# M480_v1 register map
File version: 1.0
Registers are 32-bit, read-write, reset 0x0 unless marked. A register's access mark holds for its fields unless they carry their own. Offsets are from the block's base; [hi:lo] are bit positions; {n}, {i} and the like mark numbered series.

## RTC — RTC Register Map
Base 0x40041000
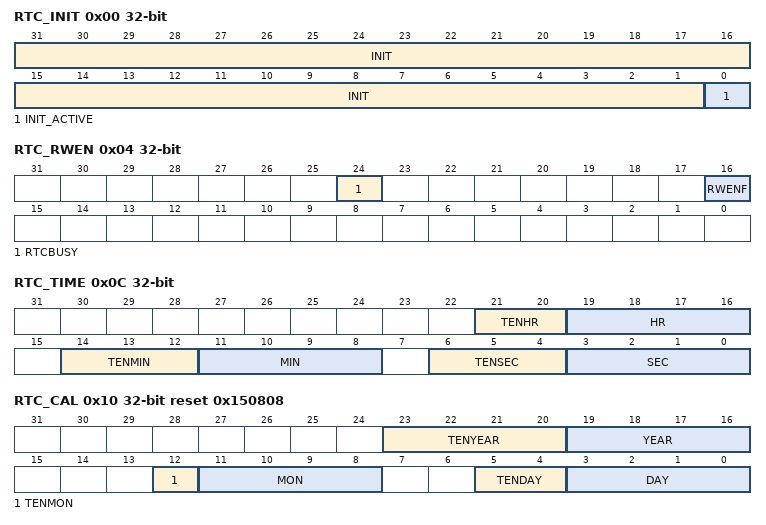
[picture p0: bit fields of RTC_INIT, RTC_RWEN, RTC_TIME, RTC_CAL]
0x00 RTC_INIT — RTC Initiation Register
  [31:1] INIT wo — RTC Initiation (Write Only). When RTC block is powered on, RTC is at reset state. User has to write a number (0x a5eb1357) to INIT to make RTC leave reset state. Once the INIT is written as 0xa5eb1357, the RTC will be in un-reset state permanently. The INIT is a write-only field and read value will be always 0.
  [0] INIT_ACTIVE ro — RTC Active Status (Read Only)
    0=RTC is at reset state; 1=RTC is at normal active state
0x04 RTC_RWEN — RTC Access Enable Register
  [24] RTCBUSY — RTC Write Busy Flag. This bit indicates RTC registers are writable or not. Note: RTCBUSY flag will be set when execute write RTC register command exceed 6 times within 1120 PCLK cycles.
    0=RTC registers are writable; 1=RTC registers can't be written. RTC is under Busy Status
  [16] RWENF ro — RTC Register Access Enable Flag (Read Only). Note: RWENF will be masked to 0 during RTCBUSY is 1, and first turn on RTCCKEN (CLK_APBCLK[1]) also.
    0=RTC register read/write Disabled; 1=RTC register read/write Enabled
0x08 RTC_FREQADJ reset 0x200000 — RTC Frequency Compensation Register
  [21:0] FREQADJ — Frequency Compensation Register. User must to get actual LXT frequency for RTC application. Note: This formula is suitable only when RTC clock source is from LXT, RTCSEL (CLK_CLKSEL3[8]) is 0.
0x0C RTC_TIME — RTC Time Loading Register
  [21:20] TENHR — 10-Hour Time Digit (0~2)When RTC runs as 12-hour time scale mode, RTC_TIME[21] (the high bit of TENHR[1:0]) means AM/PM indication (If RTC_TIME[21] is 1, it indicates PM time message.)
  [19:16] HR — 1-Hour Time Digit (0~9)
  [14:12] TENMIN — 10-Min Time Digit (0~5)
  [11:8] MIN — 1-Min Time Digit (0~9)
  [6:4] TENSEC — 10-Sec Time Digit (0~5)
  [3:0] SEC — 1-Sec Time Digit (0~9)
0x10 RTC_CAL reset 0x150808 — RTC Calendar Loading Register
  [23:20] TENYEAR — 10-Year Calendar Digit (0~9)
  [19:16] YEAR — 1-Year Calendar Digit (0~9)
  [12] TENMON — 10-Month Calendar Digit (0~1)
  [11:8] MON — 1-Month Calendar Digit (0~9)
  [5:4] TENDAY — 10-Day Calendar Digit (0~3)
  [3:0] DAY — 1-Day Calendar Digit (0~9)
0x14 RTC_CLKFMT reset 0x1 — RTC Time Scale Selection Register
  [0] _24HEN — 24-hour / 12-hour Time Scale Selection. Indicates that RTC_TIME and RTC_TALM are in 24-hour time scale or 12-hour time scale
    0=12-hour time scale with AM and PM indication selected; 1=24-hour time scale selected
0x18 RTC_WEEKDAY reset 0x6 — RTC Day of the Week Register
  [2:0] WEEKDAY — Day of the Week Register
    0=Sunday; 1=Monday; 2=Tuesday; 3=Wednesday; 4=Thursday; 5=Friday; 6=Saturday
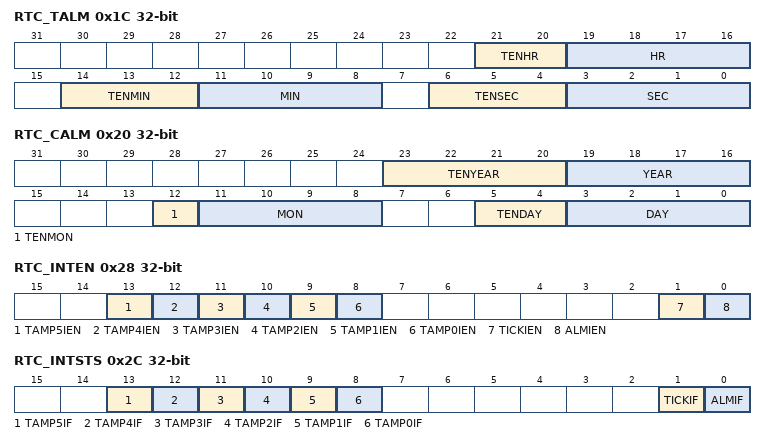
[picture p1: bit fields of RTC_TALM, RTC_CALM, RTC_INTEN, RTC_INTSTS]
0x1C RTC_TALM — RTC Time Alarm Register
  [21:20] TENHR — 10-Hour Time Digit of Alarm Setting (0~2)When RTC runs as 12-hour time scale mode, RTC_TIME[21] (the high bit of TENHR[1:0]) means AM/PM indication (If RTC_TIME[21] is 1, it indicates PM time message.)
  [19:16] HR — 1-Hour Time Digit of Alarm Setting (0~9)
  [14:12] TENMIN — 10-Min Time Digit of Alarm Setting (0~5)
  [11:8] MIN — 1-Min Time Digit of Alarm Setting (0~9)
  [6:4] TENSEC — 10-Sec Time Digit of Alarm Setting (0~5)
  [3:0] SEC — 1-Sec Time Digit of Alarm Setting (0~9)
0x20 RTC_CALM — RTC Calendar Alarm Register
  [23:20] TENYEAR — 10-Year Calendar Digit of Alarm Setting (0~9)
  [19:16] YEAR — 1-Year Calendar Digit of Alarm Setting (0~9)
  [12] TENMON — 10-Month Calendar Digit of Alarm Setting (0~1)
  [11:8] MON — 1-Month Calendar Digit of Alarm Setting (0~9)
  [5:4] TENDAY — 10-Day Calendar Digit of Alarm Setting (0~3)
  [3:0] DAY — 1-Day Calendar Digit of Alarm Setting (0~9)
0x24 RTC_LEAPYEAR ro — RTC Leap Year Indicator Register
  [0] LEAPYEAR — Leap Year Indication (Read Only)
    0=This year is not a leap year; 1=This year is leap year
0x28 RTC_INTEN — RTC Interrupt Enable Register
  [13] TAMP5IEN — Tamper 5 or Pair 2 Interrupt Enable Bit. Set TAMP5IEN to 1 can also enable chip wake-up function when tamper 5 interrupt event is generated.
    0=Tamper 5 or Pair 2 interrupt Disabled; 1=Tamper 5 or Pair 2 interrupt Enabled
  [12] TAMP4IEN — Tamper 4 Interrupt Enable Bit. Set TAMP4IEN to 1 can also enable chip wake-up function when tamper 4 interrupt event is generated.
    0=Tamper 4 interrupt Disabled; 1=Tamper 4 interrupt Enabled
  [11] TAMP3IEN — Tamper 3 or Pair 1 Interrupt Enable Bit. Set TAMP3IEN to 1 can also enable chip wake-up function when tamper 3 interrupt event is generated.
    0=Tamper 3 or Pair 1 interrupt Disabled; 1=Tamper 3 or Pair 1 interrupt Enabled
  [10] TAMP2IEN — Tamper 2 Interrupt Enable Bit. Set TAMP2IEN to 1 can also enable chip wake-up function when tamper 2 interrupt event is generated.
    0=Tamper 2 interrupt Disabled; 1=Tamper 2 interrupt Enabled
  [9] TAMP1IEN — Tamper 1 or Pair 0 Interrupt Enable Bit. Set TAMP1IEN to 1 can also enable chip wake-up function when tamper 1 interrupt event is generated.
    0=Tamper 1 or Pair 0 interrupt Disabled; 1=Tamper 1 or Pair 0 interrupt Enabled
  [8] TAMP0IEN — Tamper 0 Interrupt Enable Bit. Set TAMP0IEN to 1 can also enable chip wake-up function when tamper 0 interrupt event is generated.
    0=Tamper 0 interrupt Disabled; 1=Tamper 0 interrupt Enabled
  [1] TICKIEN — Time Tick Interrupt Enable Bit. Set TICKIEN to 1 can also enable chip wake-up function when RTC tick interrupt event is generated.
    0=RTC Time Tick interrupt Disabled; 1=RTC Time Tick interrupt Enabled
  [0] ALMIEN — Alarm Interrupt Enable Bit. Set ALMIEN to 1 can also enable chip wake-up function when RTC alarm interrupt event is generated.
    0=RTC Alarm interrupt Disabled; 1=RTC Alarm interrupt Enabled
0x2C RTC_INTSTS — RTC Interrupt Status Register
  [13] TAMP5IF — Tamper 5 or Pair 2 Interrupt Flag. This bit is set when TAMP5_PIN detected level non-equal TAMP5LV (RTC_TAMPCTL[29]) or TAMP4_PIN and TAMP5_PIN disconnected during DYNPR2EN (RTC_TAMPCTL[31]) is activated or TAMP0_PIN and TAMP5_PIN disconnected during DYNPR2EN (RTC_TAMPCTL[31]) and DYN2ISS (RTC_TAMPCTL[1]) are activated. Note1: Write 1 to clear this bit. Note2: Clear all TAPMxIF will clear RTC_TAMPTIME and RTC_TAMPCAL automatically.
    0=No Tamper 5 or Pair 2 interrupt flag is generated; 1=Tamper 5 or Pair 2 interrupt flag is generated
  [12] TAMP4IF — Tamper 4 Interrupt Flag. This bit is set when TAMP4_PIN detected level non-equal TAMP4LV (RTC_TAMPCTL[25]). Note1: Write 1 to clear this bit. Note2: Clear all TAPMxIF will clear RTC_TAMPTIME and RTC_TAMPCAL automatically.
    0=No Tamper 4 interrupt flag is generated; 1=Tamper 4 interrupt flag is generated
  [11] TAMP3IF — Tamper 3 or Pair 1 Interrupt Flag. This bit is set when TAMP3_PIN detected level non-equal TAMP3LV (RTC_TAMPCTL[21]) or TAMP2_PIN and TAMP3_PIN disconnected during DYNPR1EN (RTC_TAMPCTL[23]) is activated or TAMP0_PIN and TAMP3_PIN disconnected during DYNPR1EN (RTC_TAMPCTL[23]) and DYN1ISS (RTC_TAMPCTL[0]) are activated. Note1: Write 1 to clear this bit. Note2: Clear all TAPMxIF will clear RTC_TAMPTIME and RTC_TAMPCAL automatically.
    0=No Tamper 3 or Pair 1 interrupt flag is generated; 1=Tamper 3 or Pair 1 interrupt flag is generated
  [10] TAMP2IF — Tamper 2 Interrupt Flag. This bit is set when TAMP2_PIN detected level non-equal TAMP2LV (RTC_TAMPCTL[17]). Note1: Write 1 to clear this bit. Note2: Clear all TAPMxIF will clear RTC_TAMPTIME and RTC_TAMPCAL automatically.
    0=No Tamper 2 interrupt flag is generated; 1=Tamper 2 interrupt flag is generated
  [9] TAMP1IF — Tamper 1 or Pair 0 Interrupt Flag. This bit is set when TAMP1_PIN detected level non-equal TAMP1LV (RTC_TAMPCTL[13]) or TAMP0_PIN and TAMP1_PIN disconnected during DYNPR0EN (RTC_TAMPCTL[15]) is activated. Note1: Write 1 to clear this bit. Note2: Clear all TAPMxIF will clear RTC_TAMPTIME and RTC_TAMPCAL automatically.
    0=No Tamper 1 or Pair 0 interrupt flag is generated; 1=Tamper 1 or Pair 0 interrupt flag is generated
  [8] TAMP0IF — Tamper 0 Interrupt Flag. This bit is set when TAMP0_PIN detected level non-equal TAMP0LV (RTC_TAMPCTL[9]). Note1: Write 1 to clear this bit. Note2: Clear all TAPMxIF will clear RTC_TAMPTIME and RTC_TAMPCAL automatically.
    0=No Tamper 0 interrupt flag is generated; 1=Tamper 0 interrupt flag is generated
  [1] TICKIF — RTC Time Tick Interrupt Flag. Note: Write 1 to clear this bit.
    0=Tick condition did not occur; 1=Tick condition occurred
  [0] ALMIF — RTC Alarm Interrupt Flag. Note: Write 1 to clear this bit.
    0=Alarm condition is not matched; 1=Alarm condition is matched
0x30 RTC_TICK — RTC Time Tick Register
  [2:0] TICK — Time Tick Register. These bits are used to select RTC time tick period for Periodic Time Tick Interrupt request. Note: This register can be read back after the RTC register access enable bit RWENF (RTC_RWEN[16]) is active.
    0=Time tick is 1 second; 1=Time tick is 1/2 second; 2=Time tick is 1/4 second; 3=Time tick is 1/8 second; 4=Time tick is 1/16 second; 5=Time tick is 1/32 second; 6=Time tick is 1/64 second; 7=Time tick is 1/128 second
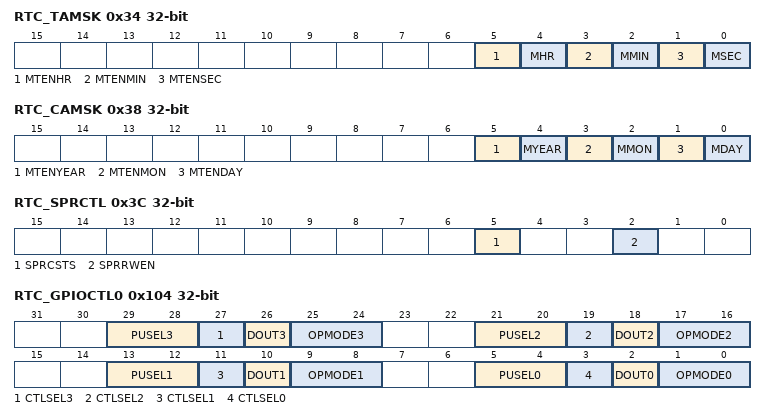
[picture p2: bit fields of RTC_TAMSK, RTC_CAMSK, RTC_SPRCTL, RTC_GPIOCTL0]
0x34 RTC_TAMSK — RTC Time Alarm Mask Register
  [5] MTENHR — Mask 10-Hour Time Digit of Alarm Setting (0~2)
  [4] MHR — Mask 1-Hour Time Digit of Alarm Setting (0~9)
  [3] MTENMIN — Mask 10-Min Time Digit of Alarm Setting (0~5)
  [2] MMIN — Mask 1-Min Time Digit of Alarm Setting (0~9)
  [1] MTENSEC — Mask 10-Sec Time Digit of Alarm Setting (0~5)
  [0] MSEC — Mask 1-Sec Time Digit of Alarm Setting (0~9)
0x38 RTC_CAMSK — RTC Calendar Alarm Mask Register
  [5] MTENYEAR — Mask 10-Year Calendar Digit of Alarm Setting (0~9)
  [4] MYEAR — Mask 1-Year Calendar Digit of Alarm Setting (0~9)
  [3] MTENMON — Mask 10-Month Calendar Digit of Alarm Setting (0~1)
  [2] MMON — Mask 1-Month Calendar Digit of Alarm Setting (0~9)
  [1] MTENDAY — Mask 10-Day Calendar Digit of Alarm Setting (0~3)
  [0] MDAY — Mask 1-Day Calendar Digit of Alarm Setting (0~9)
0x3C RTC_SPRCTL — RTC Spare Functional Control Register
  [5] SPRCSTS — SPR Clear Flag. This bit indicates if the RTC_SPR0 ~RTC_SPR19 content is cleared when specify tamper event is detected. Note1: Write 1 to clear this bit. Note2: This bit keeps 1 when RTC_INTSTS[13:8] is not equal to 0.
    0=Spare register content is not cleared; 1=Spare register content is cleared
  [2] SPRRWEN — Spare Register Enable Bit. Note: When spare register is disabled, RTC_SPR0 ~ RTC_SPR19 cannot be accessed.
    0=Spare register Disabled; 1=Spare register Enabled
{0x40+4i} RTC_SPR{i} (i=0..19) — RTC Spare Register {i}
  [31:0] SPARE — Spare Register. This field is used to store back-up information defined by user. This field will be cleared by hardware automatically once a tamper pin event is detected. Before storing back-up information in to RTC_SPRx register, user should check REWNF (RTC_RWEN[16]) is enabled.
0x100 RTC_LXTCTL reset 0xE — RTC 32.768 KHz Oscillator Control Register
  [2:1] GAIN — Oscillator Gain Option. User can select oscillator gain according to crystal external loading and operating temperature range. The larger gain value corresponding to stronger driving capability and higher power consumption.
    {v}=L{v} mode (v=0..3)
0x104 RTC_GPIOCTL0 — RTC GPIO Control 0 Register
  [29:28] PUSEL3 — IO Pull-up and Pull-down Enable Bits. Determine PF.7 I/O pull-up or pull-down. Note: Basically, the pull-up control and pull-down control has following behavior limitation. The independent pull-up / pull-down control register only valid when OPMODE2 set as input tri-state and open-drain mode.
    0=PF.7 pull-up and pull-down disable; 1=PF.7 pull-up enable; 2=PF.7 pull-down enable
  [27] CTLSEL3 — IO Pin State Backup Selection. When TAMP1EN is disabled, PF.7 pin (TAMPER1 pin) can be used as GPIO function. User can program CTLSEL3 to decide PF.7 I/O function is controlled by system power domain GPIO module or VBAT power domain RTC_GPIOCTL0 control register. PF.7 pin function and I/O status are controlled by OPMODE3[1:0] and DOUT3 after CTLSEL3 is set to 1. Note: CTLSEL3 will automatically be set by hardware to 1 when system power is off and INIT[0](RTC_INIT[0]) is 1.
    0=PF.7 pin I/O function is controlled by GPIO module; 1=PF.7 pin I/O function is controlled by VBAT power domain
  [26] DOUT3 — IO Output Data
    0=PF.7 output low; 1=PF.7 output high
  [25:24] OPMODE3 — IO Operation Mode
    0=PF.7 is input only mode; 1=PF.7 is output push pull mode; 2=PF.7 is open drain mode; 3=PF.7 is quasi-bidirectional mode
  [21:20] PUSEL2 — IO Pull-up and Pull-down Enable Bits. Determine PF.6 I/O pull-up or pull-down. Note1: Basically, the pull-up control and pull-down control has following behavior limitation. The independent pull-up / pull-down control register only valid when OPMODE2 set as input tri-state and open-drain mode.
    0=PF.6 pull-up and pull-down disable; 1=PF.6 pull-up enable; 2=PF.6 pull-down enable
  [19] CTLSEL2 — IO Pin State Backup Selection. When TAMP0EN is disabled, PF.6 pin (TAMPER0 pin) can be used as GPIO function. User can program CTLSEL2 to decide PF.6 I/O function is controlled by system power domain GPIO module or VBAT power domain RTC_GPIOCTL0 control register. PF.6 pin function and I/O status are controlled by OPMODE2[1:0] and DOUT2 after CTLSEL2 is set to 1. Note: CTLSEL2 will automatically be set by hardware to 1 when system power is off and INIT[0] (RTC_INIT[0]) is 1.
    0=PF.6 pin I/O function is controlled by GPIO module; 1=PF.6 pin I/O function is controlled by VBAT power domain
  [18] DOUT2 — IO Output Data
    0=PF.6 output low; 1=PF.6 output high
  [17:16] OPMODE2 — IO Operation Mode
    0=PF.6 is input only mode; 1=PF.6 is output push pull mode; 2=PF.6 is open drain mode; 3=PF.6 is quasi-bidirectional mode
  [13:12] PUSEL1 — IO Pull-up and Pull-down Enable Bits. Determine PF.5 I/O pull-up or pull-down. Note: Basically, the pull-up control and pull-down control has following behavior limitation. The independent pull-up / pull-down control register only valid when OPMODE2 set as input tri-state and open-drain mode.
    0=PF.5 pull-up and pull-up disable; 1=PF.5 pull-up enable; 2=PF.5 pull-down enable
  [11] CTLSEL1 — IO Pin State Backup Selection. When low speed 32 kHz oscillator is disabled, PF.5 pin (X32KI pin) can be used as GPIO function. User can program CTLSEL1 to decide PF.5 I/O function is controlled by system power domain GPIO module or VBAT power domain RTC_GPIOCTL0 control register. PF.5 pin function and I/O status are controlled by OPMODE1[1:0] and DOUT1 after CTLSEL1 is set to 1. Note: CTLSEL1 will automatically be set by hardware to 1 when system power is off and INIT[0] (RTC_INIT[0]) is 1.
    0=PF.5 pin I/O function is controlled by GPIO module; 1=PF.5 pin I/O function is controlled by VBAT power domain
  [10] DOUT1 — IO Output Data
    0=PF.5 output low; 1=PF.5 output high
  [9:8] OPMODE1 — IO Operation Mode
    0=PF.5 is input only mode; 1=PF.5 is output push pull mode; 2=PF.5 is open drain mode; 3=PF.5 is quasi-bidirectional mode
  [5:4] PUSEL0 — IO Pull-up and Pull-down Enable Bits. Determine PF.4 I/O pull-up or pull-down. Note: Basically, the pull-up control and pull-down control has following behavior limitation. The independent pull-up / pull-down control register only valid when OPMODE2 set as input tri-state and open-drain mode.
    0=PF.4 pull-up and pull-down disable; 1=PF.4 pull-up enable; 2=PF.4 pull-down enable
  [3] CTLSEL0 — IO Pin State Backup Selection. When low speed 32 kHz oscillator is disabled, PF.4 pin (X32KO pin) can be used as GPIO function. User can program CTLSEL0 to decide PF.4 I/O function is controlled by system power domain GPIO module or VBAT power domain RTC_GPIOCTL0 control register. PF.4 pin function and I/O status are controlled by OPMODE0[1:0] and DOUT0 after CTLSEL0 is set to 1. Note: CTLSEL0 will automatically be set by hardware to 1 when system power is off and INIT[0] (RTC_INIT[0]) is 1.
    0=PF.4 pin I/O function is controlled by GPIO module; 1=PF.4 pin I/O function is controlled by VBAT power domain
  [2] DOUT0 — IO Output Data
    0=PF.4 output low; 1=PF.4 output high
  [1:0] OPMODE0 — IO Operation Mode
    0=PF.4 is input only mode; 1=PF.4 is output push pull mode; 2=PF.4 is open drain mode; 3=PF.4 is quasi-bidirectional mode
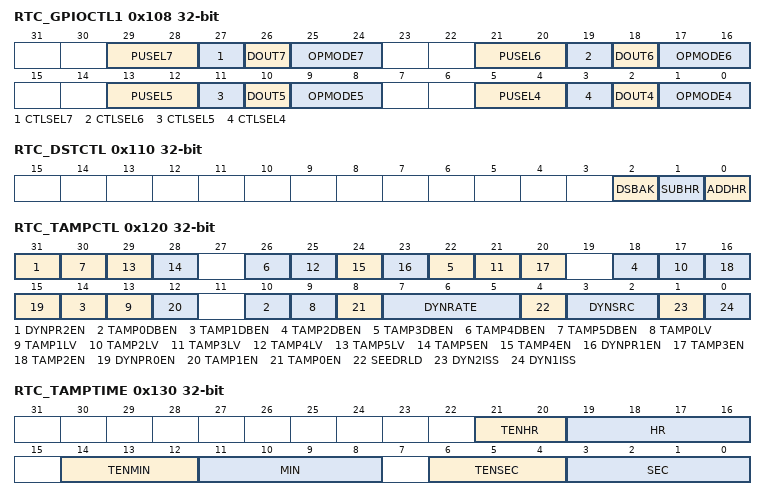
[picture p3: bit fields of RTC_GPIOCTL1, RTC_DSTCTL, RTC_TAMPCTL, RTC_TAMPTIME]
0x108 RTC_GPIOCTL1 — RTC GPIO Control 1 Register
  [29:28] PUSEL7 — IO Pull-up and Pull-down Enable Bits. Determine PF.11 I/O pull-up or pull-down. Note: Basically, the pull-up control and pull-down control has following behavior limitation. The independent pull-up / pull-down control register only valid when OPMODE2 set as input tri-state and open-drain mode.
    0=PF.11 pull-up and pull-down disable; 1=PF.11 pull-up enable; 2=PF.11 pull-down enable
  [27] CTLSEL7 — IO Pin State Backup Selection. When TAMP5EN is disabled, PF.11 pin (TAMPER5 pin) can be used as GPIO function. User can program CTLSEL7 to decide PF.11 I/O function is controlled by system power domain GPIO module or VBAT power domain RTC_GPIOCTL1 control register. PF.11 pin function and I/O status are controlled by OPMODE7[1:0] and DOUT7 after CTLSEL7 is set to 1. Note: CTLSEL7 will automatically be set by hardware to 1 when system power is off and INIT[0] (RTC_INIT[0]) is 1.
    0=PF.11 pin I/O function is controlled by GPIO module; 1=PF.11 pin I/O function is controlled by VBAT power domain
  [26] DOUT7 — IO Output Data
    0=PF.11 output low; 1=PF.11 output high
  [25:24] OPMODE7 — IO Operation Mode
    0=PF.11 is input only mode; 1=PF.11 is output push pull mode; 2=PF.11 is open drain mode; 3=PF.11 is quasi-bidirectional mode
  [21:20] PUSEL6 — IO Pull-up and Pull-down Enable Bits. Determine PF.10 I/O pull-up or pull-down. Note: Basically, the pull-up control and pull-down control has following behavior limitation. The independent pull-up / pull-down control register only valid when OPMODE2 set as input tri-state and open-drain mode.
    0=PF.10 pull-up and pull-down disable; 1=PF.10 pull-up enable; 2=PF.10 pull-down enable
  [19] CTLSEL6 — IO Pin State Backup Selection. When TAMP4EN is disabled, PF.10 pin (TAMPER4 pin) can be used as GPIO function. User can program CTLSEL6 to decide PF.10 I/O function is controlled by system power domain GPIO module or VBAT power domain RTC_GPIOCTL1 control register. PF.10 pin function and I/O status are controlled by OPMODE6[1:0] and DOUT6 after CTLSEL6 is set to 1. Note: CTLSEL6 will automatically be set by hardware to 1 when system power is off and INIT[0] (RTC_INIT[0]) is 1.
    0=PF.10 pin I/O function is controlled by GPIO module; 1=PF.10 pin I/O function is controlled by VBAT power domain
  [18] DOUT6 — IO Output Data
    0=PF.10 output low; 1=PF.10 output high
  [17:16] OPMODE6 — IO Operation Mode
    0=PF.10 is input only mode; 1=PF.10 is output push pull mode; 2=PF.10 is open drain mode; 3=PF.10 is quasi-bidirectional mode
  [13:12] PUSEL5 — IO Pull-up and Pull-down Enable Bits. Determine PF.9 I/O pull-up or pull-down. Note: Basically, the pull-up control and pull-down control has following behavior limitation. The independent pull-up / pull-down control register only valid when OPMODE2 set as input tri-state and open-drain mode.
    0=PF.9 pull-up and pull-down disable; 1=PF.9 pull-up enable; 2=PF.9 pull-down enable
  [11] CTLSEL5 — IO Pin State Backup Selection. When TAMP3EN is disabled, PF.9 pin (TAMPER3 pin) can be used as GPIO function. User can program CTLSEL5 to decide PF.9 I/O function is controlled by system power domain GPIO module or VBAT power domain RTC_GPIOCTL1 control register. PF.9 pin function and I/O status are controlled by OPMODE5[1:0] and DOUT5 after CTLSEL5 is set to 1. Note: CTLSEL5 will automatically be set by hardware to 1 when system power is off and INIT[0] (RTC_INIT[0]) is 1.
    0=PF.9 pin I/O function is controlled by GPIO module; 1=PF.9 pin I/O function is controlled by VBAT power domain
  [10] DOUT5 — IO Output Data
    0=PF.9 output low; 1=PF.9 output high
  [9:8] OPMODE5 — IO Operation Mode
    0=PF.9 is input only mode; 1=PF.9 is output push pull mode; 2=PF.9 is open drain mode; 3=PF.9 is quasi-bidirectional mode
  [5:4] PUSEL4 — IO Pull-up and Pull-down Enable Bits. Determine PF.8 I/O pull-up or pull-down. Note: Basically, the pull-up control and pull-down control has following behavior limitation. The independent pull-up / pull-down control register only valid when OPMODE2 set as input tri-state and open-drain mode.
    0=PF.8 pull-up and pull-down disable; 1=PF.8 pull-up enable; 2=PF.8 pull-down enable
  [3] CTLSEL4 — IO Pin State Backup Selection. When TAMP2EN is disabled, PF.8 pin (TAMPER2 pin) can be used as GPIO function. User can program CTLSEL4 to decide PF.8 I/O function is controlled by system power domain GPIO module or VBAT power domain RTC_GPIOCTL1 control register. PF.8 pin function and I/O status are controlled by OPMODE4[1:0] and DOUT4 after CTLSEL4 is set to 1. Note: CTLSEL4 will automatically be set by hardware to 1 when system power is off and INIT[0] (RTC_INIT[0]) is 1.
    0=PF.8 pin I/O function is controlled by GPIO module; 1=PF.8 pin I/O function is controlled by VBAT power domain
  [2] DOUT4 — IO Output Data
    0=PF.8 output low; 1=PF.8 output high
  [1:0] OPMODE4 — IO Operation Mode
    0=PF.8 is input only mode; 1=PF.8 is output push pull mode; 2=PF.8 is open drain mode; 3=PF.8 is quasi-bidirectional mode
0x110 RTC_DSTCTL — RTC Daylight Saving Time Control Register
  [2] DSBAK — Daylight Saving Back
    0=Normal mode; 1=Daylight saving mode
  [1] SUBHR — Subtract 1 Hour
    0=No effect; 1=Indicates RTC hour digit has been subtracted one hour for winter time change
  [0] ADDHR — Add 1 Hour
    0=No effect; 1=Indicates RTC hour digit has been added one hour for summer time change
0x120 RTC_TAMPCTL — RTC Tamper Pin Control Register
  [31] DYNPR2EN — Dynamic Pair 2 Enable Bit
    0=Static detect; 1=Dynamic detect
  [4n+10] TAMP{n}DBEN (n=0..5) — Tamper {n} De-bounce Enable Bit
    0=Tamper {n} de-bounce Disabled; 1=Tamper {n} de-bounce Enabled
  [4n+9] TAMP{n}LV (n=0..5) — Tamper {n} Level. This bit depends on level attribute of tamper pin for static tamper detection.
    0=Detect voltage level is low; 1=Detect voltage level is high
  [28] TAMP5EN — Tamper 5 Detect Enable Bit. Note: The reference is RTC-clock. Tamper detector need sync 2 ~ 3 RTC-clock.
    0=Tamper 5 detect Disabled; 1=Tamper 5 detect Enabled
  [24] TAMP4EN — Tamper4 Detect Enable Bit. Note1: The reference is RTC-clock. Tamper detector need sync 2 ~ 3 RTC-clock.
    0=Tamper 4 detect Disabled; 1=Tamper 4 detect Enabled
  [23] DYNPR1EN — Dynamic Pair 1 Enable Bit
    0=Static detect; 1=Dynamic detect
  [20] TAMP3EN — Tamper 3 Detect Enable Bit. Note1: The reference is RTC-clock. Tamper detector need sync 2 ~ 3 RTC-clock.
    0=Tamper 3 detect Disabled; 1=Tamper 3 detect Enabled
  [16] TAMP2EN — Tamper 2 Detect Enable Bit. Note1: The reference is RTC-clock. Tamper detector need sync 2 ~ 3 RTC-clock.
    0=Tamper 2 detect Disabled; 1=Tamper 2 detect Enabled
  [15] DYNPR0EN — Dynamic Pair 0 Enable Bit
    0=Static detect; 1=Dynamic detect
  [12] TAMP1EN — Tamper 1 Detect Enable Bit. Note1: The reference is RTC-clock. Tamper detector need sync 2 ~ 3 RTC-clock.
    0=Tamper 1 detect Disabled; 1=Tamper 1 detect Enabled
  [8] TAMP0EN — Tamper0 Detect Enable Bit. Note1: The reference is RTC-clock. Tamper detector need sync 2 ~ 3 RTC-clock.
    0=Tamper 0 detect Disabled; 1=Tamper 0 detect Enabled
  [7:5] DYNRATE — Dynamic Change Rate. This item is choice the dynamic tamper output change rate. Note: After revising this field, set SEEDRLD (RTC_TAMPCTL[4]) can reload change rate immediately.
    {v}={v+210} * RTC_CLK (v=0..7)
  [4] SEEDRLD — Reload New Seed for PRNG Engine. Setting this bit, the tamper configuration will be reload. Note: Before this bit is set, the tamper configuration should be set to complete.
    0=Generating key based on the current seed; 1=Reload new seed
  [3:2] DYNSRC — Dynamic Reference Pattern. This fields determine the new reference pattern when current pattern run out in dynamic pair mode. Note: After this bit is modified, the SEEDRLD (RTC_TAMPCTL[4]) should be set.
    1=The new reference pattern is repeated previous random value when the reference pattern run out; 3=The new reference pattern is repeated from SEED (RTC_TAMPSEED[31:0]) when the reference pattern run out
  [1] DYN2ISS — Dynamic Pair 2 Input Source Select. This bit determine Tamper 5 input is from Tamper 4 or Tamper 0 in dynamic mode. Note: This bit has effect only when DYNPR2EN (RTC_TAMPCTL[24]) and DYNPR0EN (RTC_TAMPCTL[15]) are set
    0=Tamper input is from Tamper 4; 1=Tamper input is from Tamper 0
  [0] DYN1ISS — Dynamic Pair 1 Input Source Select. This bit determine Tamper 3 input is from Tamper 2 or Tamper 0 in dynamic mode. Note: This bit is effective only when DYNPR1EN (RTC_TAMPCTL[16]) and DYNPR0EN (RTC_TAMPCTL[15]) are set
    0=Tamper input is from Tamper 2; 1=Tamper input is from Tamper 0
0x128 RTC_TAMPSEED — RTC Tamper Dynamic Seed Register
  [31:0] SEED — Seed Value
0x130 RTC_TAMPTIME ro — RTC Tamper Time Register
  [21:20] TENHR — 10-hour Time Digit of TAMPER Time (0~2). Note: 24-hour time scale only.
  [19:16] HR — 1-Hour Time Digit of TAMPER Time (0~9)
  [14:12] TENMIN — 10-Min Time Digit of TAMPER Time (0~5)
  [11:8] MIN — 1-Min Time Digit of TAMPER Time (0~9)
  [6:4] TENSEC — 10-Sec Time Digit of TAMPER Time (0~5)
  [3:0] SEC — 1-Sec Time Digit of TAMPER Time (0~9)
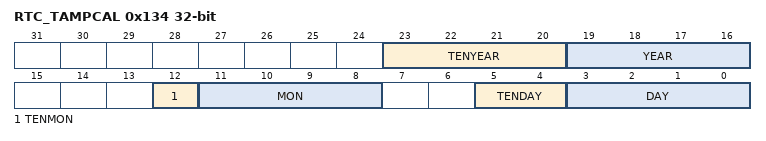
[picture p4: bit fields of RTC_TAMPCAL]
0x134 RTC_TAMPCAL ro — RTC Tamper Calendar Register
  [23:20] TENYEAR — 10-Year Calendar Digit of TAMPER Calendar (0~9)
  [19:16] YEAR — 1-Year Calendar Digit of TAMPER Calendar (0~9)
  [12] TENMON — 10-Month Calendar Digit of TAMPER Calendar (0~1)
  [11:8] MON — 1-Month Calendar Digit of TAMPER Calendar (0~9)
  [5:4] TENDAY — 10-Day Calendar Digit of TAMPER Calendar (0~3)
  [3:0] DAY — 1-Day Calendar Digit of TAMPER Calendar (0~9)
